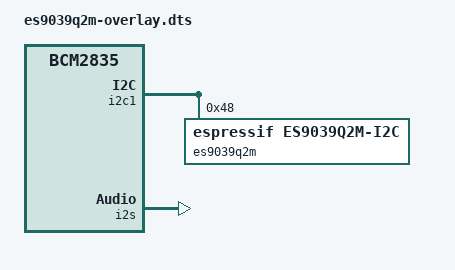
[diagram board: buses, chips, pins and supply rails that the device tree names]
/dts-v1/;
/plugin/;

/ {
    compatible = "brcm,bcm2835";

    fragment@0 {
        target = <&i2c1>;
        __overlay__ {
            #address-cells = <1>;
            #size-cells = <0>;

            es9039q2m: es9039q2m@48 {
                compatible = "espressif,es9039q2m-i2c";
                reg = <0x48>;
                #sound-dai-cells = <0>;
                status = "okay";
            };
        };
    };

    fragment@1 {
        target = <&i2s>;
        __overlay__ {
            status = "okay";
        };
    };

    fragment@2 {
        target = <&sound>;
        __overlay__ {
            compatible = "espressif,es9039q2m-machine";
            i2s-controller = <&i2s>;
            codec = <&es9039q2m>;
            status = "okay";
        };
    };
};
